# nrf52840 register map
Vendor: Nordic Semiconductor; Series: nrf52; File version: 1
CPU: CM4 r0p1, little endian, MPU, FPU, 3 interrupt priority bits
Registers are 32-bit, read-write, reset 0x0 unless marked. A register's access mark holds for its fields unless they carry their own. Offsets are from the block's base; [hi:lo] are bit positions; lines under a group give offsets from that group; {n}, {i} and the like mark numbered series; 'fields as' and 'values as' point back to an identical list.

## UICR — User information configuration registers
Base 0x10001000
{0x0+4i} UNUSED{i} (i=0..2) — Unspecified
0x10 UNUSED3 — Unspecified
{0x14+4i} NRFFW[{i}] (i=0..14) reset 0xFFFFFFFF — Description collection[n]: Reserved for Nordic firmware design
  [31:0] NRFFW — Reserved for Nordic firmware design
{0x50+4i} NRFHW[{i}] (i=0..11) reset 0xFFFFFFFF — Description collection[n]: Reserved for Nordic hardware design
  [31:0] NRFHW — Reserved for Nordic hardware design
{0x80+4i} CUSTOMER[{i}] (i=0..31) reset 0xFFFFFFFF — Description collection[n]: Reserved for customer
  [31:0] CUSTOMER — Reserved for customer
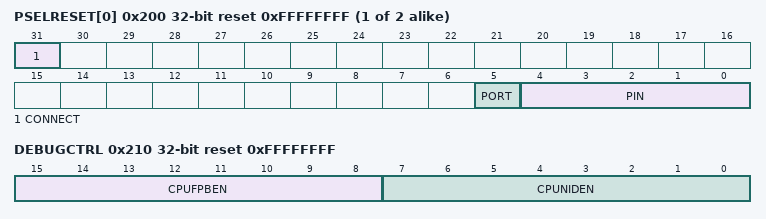
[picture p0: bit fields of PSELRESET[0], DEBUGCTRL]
{0x200+4i} PSELRESET[{i}] (i=0..1) reset 0xFFFFFFFF — Description collection[n]: Mapping of the nRESET function
  [31] CONNECT — Connection
    1=Disconnected; 0=Connected
  [5] PORT — Port number onto which nRESET is exposed
  [4:0] PIN — Pin number of PORT onto which nRESET is exposed
0x208 APPROTECT reset 0xFFFFFFFF — Access port protection
  [7:0] PALL — Enable or disable access port protection.
    255=Disabled; 0=Enabled
0x20C NFCPINS reset 0xFFFFFFFF — Setting of pins dedicated to NFC functionality: NFC antenna or GPIO
  [0] PROTECT — Setting of pins dedicated to NFC functionality
    0=Disabled (Operation as GPIO pins. Same protection as normal GPIO pins); 1=NFC (Operation as NFC antenna pins. Configures the protection for NFC operation)
0x210 DEBUGCTRL reset 0xFFFFFFFF — Processor debug control
  [15:8] CPUFPBEN — Configure CPU flash patch and breakpoint (FPB) unit behavior
    255=Enabled (Enable CPU FPB unit (default behavior)); 0=Disabled (Disable CPU FPB unit. Writes into the FPB registers will be ignored.)
  [7:0] CPUNIDEN — Configure CPU non-intrusive debug features
    255=Enabled (Enable CPU ITM and ETM functionality (default behavior)); 0=Disabled (Disable CPU ITM and ETM functionality)
0x304 REGOUT0 reset 0xFFFFFFFF — GPIO reference voltage / external output supply voltage in high voltage mode
  [2:0] VOUT — Output voltage from of REG0 regulator stage. The maximum output voltage from this stage is given as VDDH - VEXDIF.
    0=1V8 (1.8 V); 1=2V1 (2.1 V); 2=2V4 (2.4 V); 3=2V7 (2.7 V); 4=3V0 (3.0 V); 5=3V3 (3.3 V); 7=DEFAULT (Default voltage: 1.8 V)

## SPI0 — Serial Peripheral Interface 0
Base 0x40003000
Same registers: SPI1 0x40004000, SPI2 0x40023000
0x108 EVENTS_READY — TXD byte sent and RXD byte received
  [0] EVENTS_READY
0x304 INTENSET — Enable interrupt
  [2] READY — Write '1' to enable interrupt for READY event
    on read: 0=Disabled (Read: Disabled); 1=Enabled (Read: Enabled) | on write: 1=Set (Enable)
0x308 INTENCLR — Disable interrupt
  [2] READY — Write '1' to disable interrupt for READY event
    on read: 0=Disabled (Read: Disabled); 1=Enabled (Read: Enabled) | on write: 1=Clear (Disable)
0x500 ENABLE — Enable SPI
  [3:0] ENABLE — Enable or disable SPI
    0=Disabled (Disable SPI); 1=Enabled (Enable SPI)
0x508 PSEL group — Unspecified
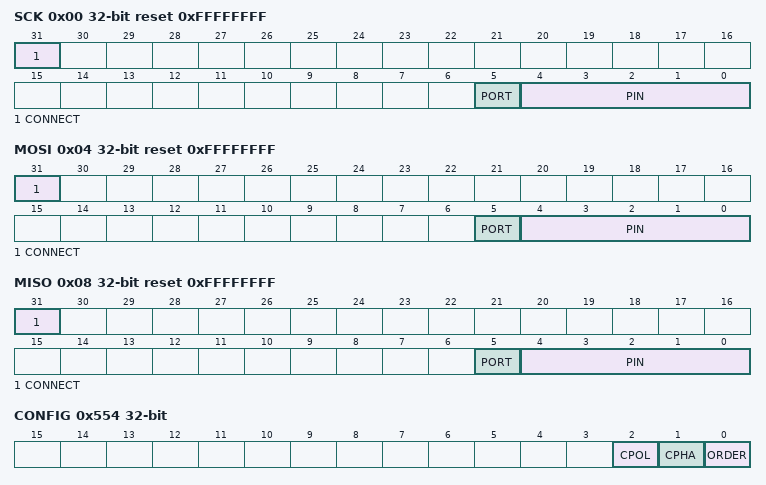
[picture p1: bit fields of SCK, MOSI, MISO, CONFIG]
  0x00 SCK reset 0xFFFFFFFF — Pin select for SCK
    [31] CONNECT — Connection
      1=Disconnected; 0=Connected
    [5] PORT — Port number
    [4:0] PIN — Pin number
  0x04 MOSI reset 0xFFFFFFFF — Pin select for MOSI signal
    fields as PSEL.SCK
  0x08 MISO reset 0xFFFFFFFF — Pin select for MISO signal
    fields as PSEL.SCK
0x518 RXD ro read-has-side-effects
  [7:0] RXD — RX data received. Double buffered
0x51C TXD
  [7:0] TXD — TX data to send. Double buffered
0x524 FREQUENCY reset 0x4000000 — SPI frequency. Accuracy depends on the HFCLK source selected.
  [31:0] FREQUENCY — SPI master data rate
    0x2000000=K125 (125 kbps); 0x4000000=K250 (250 kbps); 0x8000000=K500 (500 kbps); 0x10000000=M1 (1 Mbps); 0x20000000=M2 (2 Mbps); 0x40000000=M4 (4 Mbps); 0x80000000=M8 (8 Mbps)
0x554 CONFIG — Configuration register
  [2] CPOL — Serial clock (SCK) polarity
    0=ActiveHigh; 1=ActiveLow
  [1] CPHA — Serial clock (SCK) phase
    0=Leading (Sample on leading edge of clock, shift serial data on trailing edge); 1=Trailing (Sample on trailing edge of clock, shift serial data on leading edge)
  [0] ORDER — Bit order
    0=MsbFirst (Most significant bit shifted out first); 1=LsbFirst (Least significant bit shifted out first)
